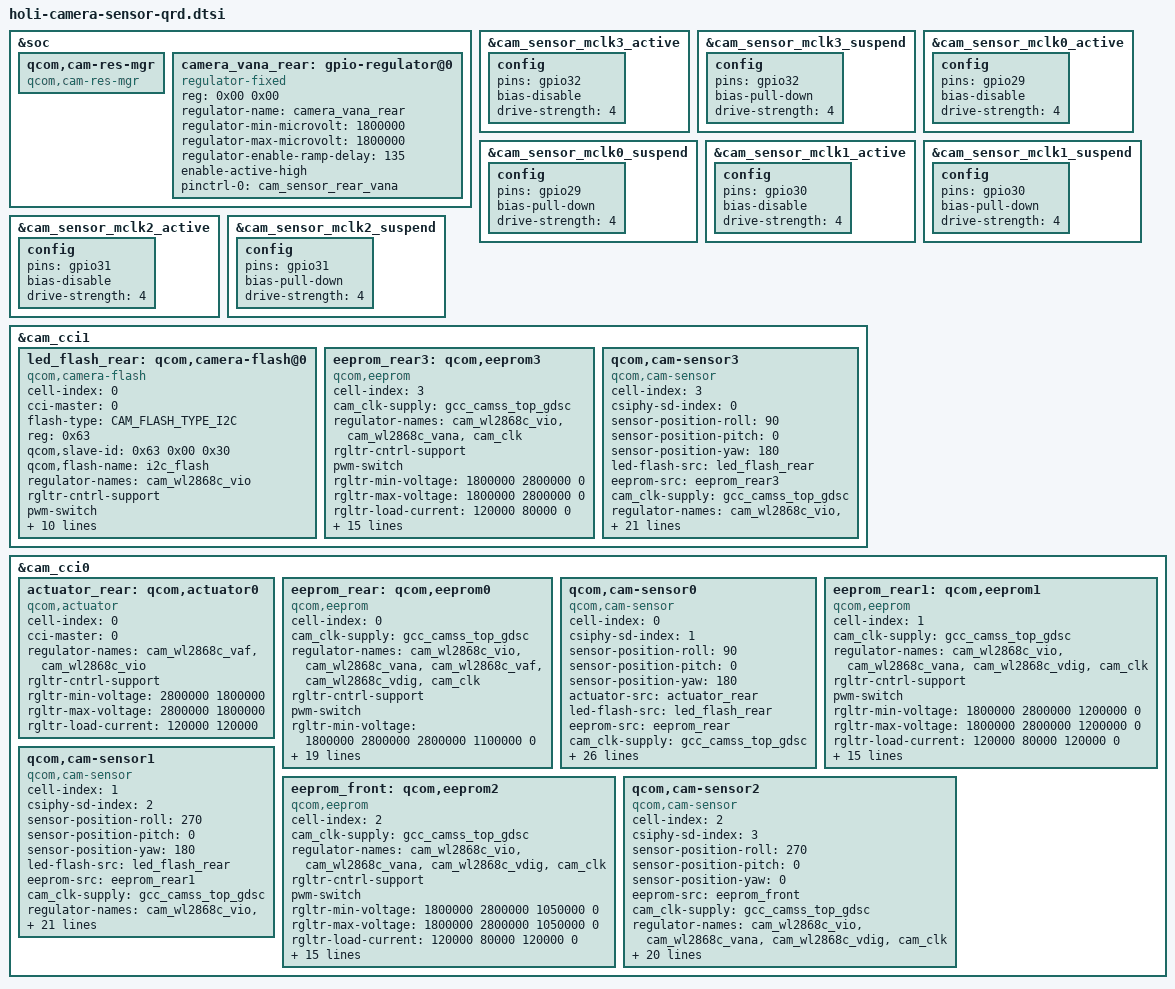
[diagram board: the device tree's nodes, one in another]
#include <dt-bindings/clock/qcom,gcc-blair.h>
#include <dt-bindings/msm/msm-camera.h>
&soc {

	qcom,cam-res-mgr {
		compatible = "qcom,cam-res-mgr";
		status = "ok";
	};

	camera_vana_rear: gpio-regulator@0 {
		compatible = "regulator-fixed";
		reg = <0x00 0x00>;
		regulator-name = "camera_vana_rear";
		regulator-min-microvolt = <1800000>;
		regulator-max-microvolt = <1800000>;
		regulator-enable-ramp-delay = <135>;
		enable-active-high;
		pinctrl-names = "default";
		pinctrl-0 = <&cam_sensor_rear_vana>;
	};
};

/********************modify mclk current value********************/
&cam_sensor_mclk3_active{
	config {
		pins = "gpio32";
		bias-disable; /* No PULL */
		drive-strength = <4>; /* 4 MA */
	};
};

&cam_sensor_mclk3_suspend{
	config {
		pins = "gpio32";
		bias-pull-down; /* PULL DOWN */
		drive-strength = <4>; /* 4 MA */
	};
};

&cam_sensor_mclk0_active{
	config {
		pins = "gpio29";
		bias-disable; /* No PULL */
		drive-strength = <4>; /* 4 MA */
	};
};

&cam_sensor_mclk0_suspend{
	config {
		pins = "gpio29";
		bias-pull-down; /* PULL DOWN */
		drive-strength = <4>; /* 4 MA */
	};
};

&cam_sensor_mclk1_active{
	config {
		pins = "gpio30";
		bias-disable; /* No PULL */
		drive-strength = <4>; /* 4 MA */
	};
};

&cam_sensor_mclk1_suspend{
	config {
		pins = "gpio30";
		bias-pull-down; /* PULL DOWN */
		drive-strength = <4>; /* 4 MA */
	};
};


&cam_sensor_mclk2_active{
	config {
		pins = "gpio31";
		bias-disable; /* No PULL */
		drive-strength = <4>; /* 4 MA */
	};
};

&cam_sensor_mclk2_suspend{
	config {
		pins = "gpio31";
		bias-pull-down; /* PULL DOWN */
		drive-strength = <4>; /* 4 MA */
	};
};

&cam_cci1 {
	led_flash_rear:qcom,camera-flash@0 {
		cell-index = <0>;
		compatible = "qcom,camera-flash";
		cci-master = <0>;
		flash-type = <CAM_FLASH_TYPE_I2C>;
		reg = <0x63>;
		status = "ok";
		qcom,slave-id = <0x63 0x00 0x30>;
		qcom,flash-name = "i2c_flash";
		//qcom,flash-type = <1>;
		//cam_vdig-supply = <&pm6125_l3>;
		//cam_clk-supply = <&gcc_camss_top_gdsc>;
		regulator-names = "cam_wl2868c_vio";
		rgltr-cntrl-support;
		pwm-switch;
		rgltr-min-voltage = <1800000>;
		rgltr-max-voltage = <1800000>;
		rgltr-load-current = <120000>;
		qcom,gpio-no-mux = <0>;
		gpios = <&tlmm 51 0>,
			  <&tlmm 119 0>;
		qcom,gpio-flash-en = <0>;
		qcom,gpio-flash-now = <1>;
		gpio-req-tbl-num = <0 1>;
		gpio-req-tbl-flags = <0 0>;
		gpio-req-tbl-label = "FLASH_EN",
                        "FLASH_NOW";
	};
	eeprom_rear3: qcom,eeprom3 {
		cell-index = <3>;
		compatible = "qcom,eeprom";
		cam_clk-supply = <&gcc_camss_top_gdsc>;
		regulator-names = "cam_wl2868c_vio", "cam_wl2868c_vana", "cam_clk";
		rgltr-cntrl-support;
		pwm-switch;
		rgltr-min-voltage = <1800000 2800000 0>;
		rgltr-max-voltage = <1800000 2800000 0>;
		rgltr-load-current = <120000 80000 0>;
		gpio-no-mux = <0>;
		pinctrl-names = "cam_default", "cam_suspend";
		pinctrl-0 = <&cam_sensor_mclk1_active
				&cam_sensor_rear1_reset_active>;
		pinctrl-1 = <&cam_sensor_mclk1_suspend
				&cam_sensor_rear1_reset_suspend>;
		gpios = <&tlmm 30 0>,
			<&tlmm 35 0>;
		gpio-reset = <1>;
		gpio-req-tbl-num = <0 1>;
		gpio-req-tbl-flags = <1 0>;
		gpio-req-tbl-label = "CAMIF_MCLK1",
                         "CAM_RESET1";
		sensor-mode = <0>;
		cci-master = <0>;
		status = "ok";
		clocks = <&gcc GCC_CAMSS_MCLK1_CLK>;
		clock-names = "cam_clk";
		clock-cntl-level = "turbo";
		clock-rates = <24000000>;
	};

	/*Rear Aux2*/
	qcom,cam-sensor3 {
		cell-index = <3>;
		compatible = "qcom,cam-sensor";
		csiphy-sd-index = <0>;
		sensor-position-roll = <90>;
		sensor-position-pitch = <0>;
		sensor-position-yaw = <180>;
        led-flash-src = <&led_flash_rear>;
		//led-flash-src = <&led_flash_rear_aux2>;
		eeprom-src = <&eeprom_rear3>;
		//cam_vio-supply = <&L6P>;
		//cam_vana-supply = <&L3P>;
		//cam_vdig-supply = <&L1P>;
		cam_clk-supply = <&gcc_camss_top_gdsc>;
		regulator-names = "cam_wl2868c_vio", "cam_wl2868c_vana", "cam_clk";
		rgltr-cntrl-support;
		pwm-switch;
		rgltr-min-voltage = <1800000 2800000 0>;
		rgltr-max-voltage = <1800000 2800000 0>;
		rgltr-load-current = <120000 80000 0>;
		gpio-no-mux = <0>;
		pinctrl-names = "cam_default", "cam_suspend";
		pinctrl-0 = <&cam_sensor_mclk1_active
				&cam_sensor_rear1_reset_active>;
		pinctrl-1 = <&cam_sensor_mclk1_suspend
				&cam_sensor_rear1_reset_suspend>;
		gpios = <&tlmm 30 0>,
			<&tlmm 35 0>;
		gpio-reset = <1>;
		gpio-req-tbl-num = <0 1>;
		gpio-req-tbl-flags = <1 0>;
		gpio-req-tbl-label = "CAMIF_MCLK1",
					"CAM_RESET1";
		sensor-mode = <0>;
		cci-master = <0>;
		status = "ok";
		clocks = <&gcc GCC_CAMSS_MCLK1_CLK>;
		clock-names = "cam_clk";
		clock-cntl-level = "turbo";
		clock-rates = <24000000>;
	};
};

&cam_cci0 {
	actuator_rear: qcom,actuator0 {
		cell-index = <0>;
		compatible = "qcom,actuator";
		cci-master= <0>;
		//cam_vaf-supply = <&pm6125_l3>;
		regulator-names = "cam_wl2868c_vaf","cam_wl2868c_vio";
		rgltr-cntrl-support;
		rgltr-min-voltage = <2800000 1800000>;
		rgltr-max-voltage = <2800000 1800000>;
		rgltr-load-current = <120000 120000>;
		status = "ok";
	};

	eeprom_rear: qcom,eeprom0 {
		cell-index = <0>;
		compatible = "qcom,eeprom";
		cam_clk-supply = <&gcc_camss_top_gdsc>;
		regulator-names = "cam_wl2868c_vio", "cam_wl2868c_vana", "cam_wl2868c_vaf", "cam_wl2868c_vdig",
			"cam_clk";
		rgltr-cntrl-support;
		pwm-switch;
		rgltr-min-voltage = <1800000 2800000 2800000 1100000 0>;
		rgltr-max-voltage = <1800000 2800000 2800000 1100000 0>;
		rgltr-load-current = <120000 80000   100000  120000 0>;
		gpio-no-mux = <0>;
		pinctrl-names = "cam_default", "cam_suspend";
		pinctrl-0 = <&cam_sensor_mclk0_active
                 &cam_sensor_rear0_reset_active>;
		pinctrl-1 = <&cam_sensor_mclk0_suspend
                 &cam_sensor_rear0_reset_suspend>;
		gpios = <&tlmm 29 0>,
			  <&tlmm 34 0>;
		gpio-reset = <1>;
		gpio-req-tbl-num = <0 1>;
		gpio-req-tbl-flags = <1 0>;
		gpio-req-tbl-label = "CAMIF_MCLK0",
                         "CAM_RESET0";
		sensor-mode = <0>;
		cci-master = <0>;
		status = "ok";
		clocks = <&gcc GCC_CAMSS_MCLK0_CLK>;
		clock-names = "cam_clk";
		clock-cntl-level = "turbo";
		clock-rates = <24000000>;
	};

    /* Rear*/
	qcom,cam-sensor0 {
		cell-index = <0>;
		compatible = "qcom,cam-sensor";
		csiphy-sd-index = <1>;
		sensor-position-roll = <90>;
		sensor-position-pitch = <0>;
		sensor-position-yaw = <180>;
		actuator-src = <&actuator_rear>;
		led-flash-src = <&led_flash_rear>;
		eeprom-src = <&eeprom_rear>;
		//cam_vio-supply = <&L6P>;
		//cam_vana-supply = <&L4P>;
		//cam_vaf-supply = <&L5P>;
		//cam_vdig-supply = <&L2P>;
		cam_clk-supply = <&gcc_camss_top_gdsc>;
		regulator-names = "cam_wl2868c_vio", "cam_wl2868c_vana", "cam_wl2868c_vaf", "cam_wl2868c_vdig",
			"cam_clk";
		rgltr-cntrl-support;
		pwm-switch;
		rgltr-min-voltage = <1800000 2800000 2800000 1100000 0>;
		rgltr-max-voltage = <1800000 2800000 2800000 1100000 0>;
		rgltr-load-current = <120000 80000   100000  120000 0>;
		gpio-no-mux = <0>;
		pinctrl-names = "cam_default", "cam_suspend";
		pinctrl-0 = <&cam_sensor_mclk0_active
				&cam_sensor_rear0_reset_active>;
		pinctrl-1 = <&cam_sensor_mclk0_suspend
				&cam_sensor_rear0_reset_suspend>;
		gpios = <&tlmm 29 0>,
			<&tlmm 34 0>;
		gpio-reset = <1>;
		gpio-req-tbl-num = <0 1>;
		gpio-req-tbl-flags = <1 0>;
		gpio-req-tbl-label = "CAMIF_MCLK0",
					"CAM_RESET0";
		sensor-mode = <0>;
		cci-master = <0>;
		status = "ok";
		clocks = <&gcc GCC_CAMSS_MCLK0_CLK>;
		clock-names = "cam_clk";
		clock-cntl-level = "turbo";
		clock-rates = <24000000>;
	};
	eeprom_rear1: qcom,eeprom1 {
		cell-index = <1>;
		compatible = "qcom,eeprom";
		cam_clk-supply = <&gcc_camss_top_gdsc>;
        regulator-names = "cam_wl2868c_vio", "cam_wl2868c_vana", "cam_wl2868c_vdig",
            "cam_clk";
        rgltr-cntrl-support;
        pwm-switch;
        rgltr-min-voltage = <1800000  2800000 1200000 0>;
        rgltr-max-voltage = <1800000  2800000 1200000 0>;
        rgltr-load-current = <120000  80000   120000  0>;
		gpio-no-mux = <0>;
		pinctrl-names = "cam_default", "cam_suspend";
		pinctrl-0 = <&cam_sensor_mclk2_active
                 &cam_sensor_rear2_reset_active>;
		pinctrl-1 = <&cam_sensor_mclk2_suspend
                 &cam_sensor_rear2_reset_suspend>;
		gpios = <&tlmm 31 0>,
			  <&tlmm 36 0>;
		gpio-reset = <1>;
		gpio-req-tbl-num = <0 1>;
		gpio-req-tbl-flags = <1 0>;
		gpio-req-tbl-label = "CAMIF_MCLK2",
                         "CAM_RESET2";
		sensor-mode = <0>;
		cci-master = <1>;
		status = "ok";
		clocks = <&gcc GCC_CAMSS_MCLK2_CLK>;
		clock-names = "cam_clk";
		clock-cntl-level = "turbo";
		clock-rates = <24000000>;
	};
	/*Rear Aux wide */
	qcom,cam-sensor1 {
		cell-index = <1>;
		compatible = "qcom,cam-sensor";
		csiphy-sd-index = <2>;
		sensor-position-roll = <270>;
		sensor-position-pitch = <0>;
		sensor-position-yaw = <180>;
        led-flash-src = <&led_flash_rear>;
        eeprom-src = <&eeprom_rear1>;
        cam_clk-supply = <&gcc_camss_top_gdsc>;
        regulator-names = "cam_wl2868c_vio", "cam_wl2868c_vana", "cam_wl2868c_vdig",
            "cam_clk";
        rgltr-cntrl-support;
        pwm-switch;
        rgltr-min-voltage = <1800000 2800000  1200000 0>;
        rgltr-max-voltage = <1800000 2800000  1200000 0>;
        rgltr-load-current = <120000 80000    120000 0>;
		gpio-no-mux = <0>;
		pinctrl-names = "cam_default", "cam_suspend";
		pinctrl-0 = <&cam_sensor_mclk2_active
                 &cam_sensor_rear2_reset_active>;
		pinctrl-1 = <&cam_sensor_mclk2_suspend
                 &cam_sensor_rear2_reset_suspend>;
		gpios = <&tlmm 31 0>,
			<&tlmm 36 0>;
		gpio-reset = <1>;
		gpio-req-tbl-num = <0 1>;
		gpio-req-tbl-flags = <1 0>;
		gpio-req-tbl-label = "CAMIF_MCLK2",
                         "CAM_RESET2";
		sensor-mode = <0>;
		cci-master = <1>;
		status = "ok";
		clocks = <&gcc GCC_CAMSS_MCLK2_CLK>;
		clock-names = "cam_clk";
		clock-cntl-level = "turbo";
		clock-rates = <24000000>;
	};

	eeprom_front: qcom,eeprom2 {
		cell-index = <2>;
		compatible = "qcom,eeprom";
		cam_clk-supply = <&gcc_camss_top_gdsc>;
		regulator-names = "cam_wl2868c_vio", "cam_wl2868c_vana", "cam_wl2868c_vdig",
            "cam_clk";
		rgltr-cntrl-support;
		pwm-switch;
        rgltr-min-voltage = <1800000 2800000 1050000 0>;
        rgltr-max-voltage = <1800000 2800000 1050000 0>;
        rgltr-load-current = <120000 80000   120000  0>;
		gpio-no-mux = <0>;
		pinctrl-names = "cam_default", "cam_suspend";
		pinctrl-0 = <&cam_sensor_mclk3_active
                 &cam_sensor_front0_reset_active>;
		pinctrl-1 = <&cam_sensor_mclk3_suspend
                 &cam_sensor_front0_reset_suspend>;
		gpios = <&tlmm 32 0>,
			  <&tlmm 37 0>;
		gpio-reset = <1>;
		gpio-req-tbl-num = <0 1>;
		gpio-req-tbl-flags = <1 0>;
		gpio-req-tbl-label = "CAMIF_MCLK3",
                         "CAM_RESET3";
		sensor-mode = <0>;
		cci-master = <1>;
		status = "ok";
		clocks = <&gcc GCC_CAMSS_MCLK3_CLK>;
		clock-names = "cam_clk";
		clock-cntl-level = "turbo";
		clock-rates = <24000000>;
	};

        /*Front*/
	qcom,cam-sensor2 {
		cell-index = <2>;
		compatible = "qcom,cam-sensor";
		csiphy-sd-index = <3>;
		sensor-position-roll = <270>;
		sensor-position-pitch = <0>;
		sensor-position-yaw = <0>;
        eeprom-src = <&eeprom_front>;
        cam_clk-supply = <&gcc_camss_top_gdsc>;
        regulator-names = "cam_wl2868c_vio", "cam_wl2868c_vana", "cam_wl2868c_vdig",
            "cam_clk";
        rgltr-cntrl-support;
        pwm-switch;
        rgltr-min-voltage = <1800000 2800000  1050000 0>;
        rgltr-max-voltage = <1800000 2800000  1050000 0>;
        rgltr-load-current = <120000 80000    120000 0>;
		gpio-no-mux = <0>;
		pinctrl-names = "cam_default", "cam_suspend";
		pinctrl-0 = <&cam_sensor_mclk3_active
                 &cam_sensor_front0_reset_active>;
		pinctrl-1 = <&cam_sensor_mclk3_suspend
                 &cam_sensor_front0_reset_suspend>;
		gpios = <&tlmm 32 0>,
			  <&tlmm 37 0>;
		gpio-reset = <1>;
		gpio-req-tbl-num = <0 1>;
		gpio-req-tbl-flags = <1 0>;
		gpio-req-tbl-label = "CAMIF_MCLK3",
                         "CAM_RESET3";
		sensor-mode = <0>;
		cci-master = <1>;
		status = "ok";
		clocks = <&gcc GCC_CAMSS_MCLK3_CLK>;
		clock-names = "cam_clk";
		clock-cntl-level = "turbo";
		clock-rates = <24000000>;
	};
};
